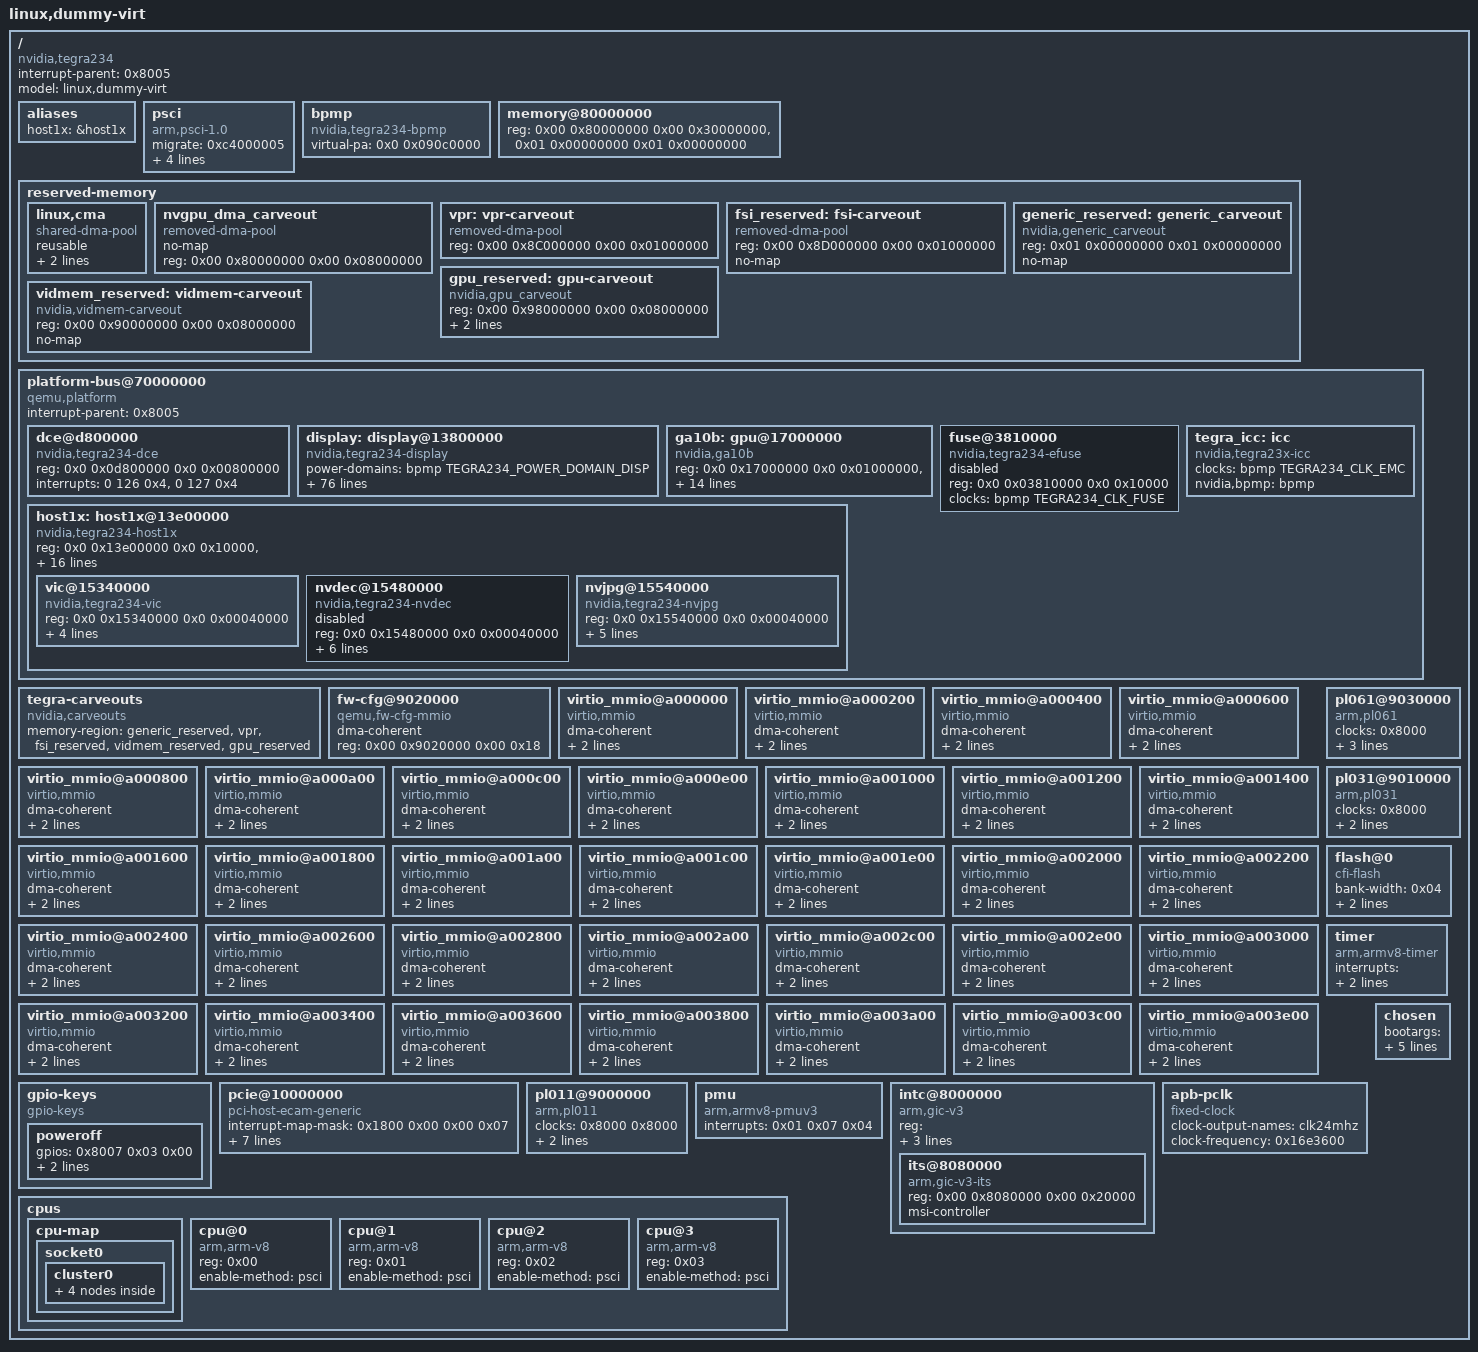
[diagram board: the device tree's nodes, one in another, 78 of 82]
// SPDX-License-Identifier: GPL-2.0-only
// SPDX-FileCopyrightText: Copyright (c) 2023, NVIDIA CORPORATION & AFFILIATES.  All rights reserved.

#include <dt-bindings/clock/tegra234-clock.h>
#include <dt-bindings/reset/tegra234-reset.h>
#include <dt-bindings/mailbox/tegra186-hsp.h>
#include <dt-bindings/memory/tegra234-mc.h>
#include <dt-bindings/interrupt-controller/irq.h>
#include <dt-bindings/interrupt-controller/arm-gic.h>
#include <dt-bindings/interrupt/tegra234-irq.h>
#include <dt-bindings/gpio/tegra234-gpio.h>
#include <dt-bindings/p2u/tegra234-p2u.h>
#include <dt-bindings/power/tegra234-powergate.h>
#include <dt-bindings/pinctrl/pinctrl-tegra.h>

/dts-v1/;


/ {
	interrupt-parent = <0x8005>;
	model = "linux,dummy-virt";
	#size-cells = <0x02>;
	#address-cells = <0x02>;

	// Some drivers need that the root node has this compatible property
	compatible = "nvidia,tegra234";

	aliases {
		host1x = &host1x;
	};

	psci {
		migrate = <0xc4000005>;
		cpu_on = <0xc4000003>;
		cpu_off = <0x84000002>;
		cpu_suspend = <0xc4000001>;
		method = "hvc";
		compatible = "arm,psci-1.0\0arm,psci-0.2\0arm,psci";
	};

	bpmp: bpmp {
		compatible = "nvidia,tegra234-bpmp", "nvidia,tegra186-bpmp";
		virtual-pa = <0x0 0x090c0000>; 
		#clock-cells = <1>;
		#reset-cells = <1>;
		#power-domain-cells = <1>;
		status = "okay";
	};

	// QEMU add the main main memory here (6GB), but we have to define the
	// passthrough memory regions.
	memory@80000000 {
		reg = <0x00 0x80000000 0x00 0x30000000>,  // For CMA regions
		      <0x01 0x00000000 0x01 0x00000000>;  // For GPU VRAM
		device_type = "memory";
	};

	reserved-memory {
		#address-cells = <2>;
		#size-cells = <2>;
		ranges;

		// Reserve the passthrough CMA ram region as CMA for the VM
		linux,cma {
			compatible = "shared-dma-pool";
			reusable;
			reg = <0x00 0x88000000 0x00 0x04000000>; // 64MB
			linux,cma-default;
			status = "okay";
		};

		// Dedicated CMA region for the GPU
		nvgpu_dma_carveout:  nvgpu_dma_carveout{
			compatible = "removed-dma-pool";
			no-map;
			reg = <0x00 0x80000000 0x00 0x08000000>; // 128MB
			status = "okay";
		};

		// Carveout needed by the NVMAP driver
		vpr: vpr-carveout {
			compatible = "removed-dma-pool";
			reg = <0x00 0x8C000000 0x00 0x01000000>; // 16MB
			status = "okay";
		};

		// Carveout needed by the NVMAP driver
		fsi_reserved: fsi-carveout {
			compatible = "removed-dma-pool";
			reg = <0x00 0x8D000000 0x00 0x01000000>; // 16MB
			no-map;
			status = "okay";
		};

		// Carveout for GPU VRAM
		generic_reserved: generic_carveout {
			compatible = "nvidia,generic_carveout";
			reg = <0x01 0x00000000 0x01 0x00000000>; // 4GB
			no-map;
			status = "okay";
		};

		// Carveout needed by the NVMAP driver
		vidmem_reserved: vidmem-carveout {
			compatible = "nvidia,vidmem-carveout";
			reg = <0x00 0x90000000 0x00 0x08000000>; // 128MB
			no-map;
			status = "okay";
		};

		// Carveout for extra GPU DMA operations
		gpu_reserved: gpu-carveout {
			compatible = "nvidia,gpu_carveout";
			reg = <0x00 0x98000000 0x00 0x08000000>; // 128MB
			granule-size = <64>;
			no-map;
			status = "okay";
		};
	};


	platform-bus@70000000 {
		interrupt-parent = <0x8005>;

		// QEMU does not map 1:1 the platform devices, so we have to define the
		// address translation here.
		// To get the address of the devices run in the QEMU console: info mtree -f
		//        From            To              Size
		ranges = <0x00 0x17000000 0x00 0x64000000 0x00 0x01000000>,     // 0x64000000-0000000064ffffff (prio 0, ramd): VFIO 17000000.gpu region 0
		         <0x00 0x18000000 0x00 0x65000000 0x00 0x01000000>,     // 0x65000000-0000000065ffffff (prio 0, ramd): VFIO 17000000.gpu region 1
				 <0x00 0x03b41000 0x00 0x66000000 0x00 0x00001000>,     // 0x66000000-0000000066000fff (prio 0, ramd): VFIO 17000000.gpu region 2
				 <0x00 0x03810000 0x00 0x80000000 0x00 0x00010000>,     // Dummmy address for fues
				 
				 <0x00 0x13800000 0x00 0x66200000 0x00 0x000EFFFF>,     // 0x66200000-00000000662efffe (prio 0, i/o): VFIO 13800000.display region 00
				 <0x00 0x155C0000 0x00 0x660e0000 0x00 0x0000FFFF>,     // 0x660e0000-00000000660efffe (prio 0, i/o): VFIO 13800000.display region 1
				 <0x00 0x0242c000 0x00 0x66001000 0x00 0x00001000>,     // 0x66001000-0000000066001fff (prio 0, ramd): VFIO 13800000.display region 2
				 <0x00 0x03990000 0x00 0x660f0000 0x00 0x00010000>,     // 0x660f0000-00000000660fffff (prio 0, ramd): VFIO 13800000.display region 3
				 
				 <0x00 0x0d800000 0x00 0x66800000 0x00 0x00800000>,     // 0x66800000-0000000066ffffff (prio 0, ramd): VFIO d800000.dce region 0

				 <0x00 0x13e00000 0x00 0x66010000 0x00 0x00010000>,     // 0x66010000-000000006601ffff (prio 0, ramd): VFIO 13e00000.host1x_pt region 0
				 <0x00 0x13e10000 0x00 0x66020000 0x00 0x00010000>,     // 0x66020000-000000006602ffff (prio 0, ramd): VFIO 13e00000.host1x_pt region 1
				 <0x00 0x13e40000 0x00 0x66030000 0x00 0x00010000>,     // 0x66030000-000000006603ffff (prio 0, ramd): VFIO 13e00000.host1x_pt region 2
				 <0x00 0x13ef0000 0x00 0x66080000 0x00 0x00060000>,     // 0x66080000-00000000660dffff (prio 0, ramd): VFIO 13e00000.host1x_pt region 3
				 <0x00 0x15340000 0x00 0x66040000 0x00 0x00040000>,     // 0x66040000-000000006607ffff (prio 0, ramd): VFIO 15340000.vic region 0
				 <0x00 0x15480000 0x00 0x66100000 0x00 0x00040000>,     // 0x66100000-000000006613ffff (prio 0, ramd): VFIO 15480000.nvdec region 0
				 <0x00 0x15540000 0x00 0x66140000 0x00 0x00040000>;     // 0x66140000-000000006617ffff (prio 0, ramd): VFIO 15540000.nvjpg region 0


		#address-cells = <0x02>;
		#size-cells = <0x02>;
		compatible = "qemu,platform\0simple-bus";

		// Here are defined the passthrough devices
		// The commented properties are not needed for the passthrough,
		// or are not supported, because the dependency is not passedthrough 
		// to the VM, for instance the iommus.

		dce@d800000 {
			compatible = "nvidia,tegra234-dce";
			reg = <0x0 0x0d800000 0x0 0x00800000>;
			//dma-coherent;
			interrupts =
				<0 126 0x4>,
				<0 127 0x4>;
			interrupt-names = "wdt-remote",
				"dce-sm0";
			//iommus = <&smmu_niso0 TEGRA234_SID_DCE>;
			status = "okay";
		};


		display: display@13800000 {
			compatible = "nvidia,tegra234-display";
			power-domains = <&bpmp TEGRA234_POWER_DOMAIN_DISP>;
			nvidia,num-dpaux-instance = <1>;
			reg-names = "nvdisplay", "dpaux0", "hdacodec", "mipical";
			reg = <0x0 0x13800000 0x0 0xEFFFF    /* nvdisplay */
				0x0 0x155C0000 0x0 0xFFFF     /* dpaux0 */
				0x0 0x0242c000 0x0 0x1000     /* hdacodec */
				0x0 0x03990000 0x0 0x10000>;  /* mipical */
			interrupt-names = "nvdisplay", "dpaux0", "hdacodec";
			interrupts = <0 128 4
				0 129 4
				0 130 4>;
			nvidia,bpmp = <&bpmp>;
			clocks = <&bpmp TEGRA234_CLK_HUB>,
				<&bpmp TEGRA234_CLK_DISP>,
				<&bpmp TEGRA234_CLK_NVDISPLAY_P0>,
				<&bpmp TEGRA234_CLK_NVDISPLAY_P1>,
				<&bpmp TEGRA234_CLK_DPAUX>,
				<&bpmp TEGRA234_CLK_FUSE>,
				<&bpmp TEGRA234_CLK_DSIPLL_VCO>,
				<&bpmp TEGRA234_CLK_DSIPLL_CLKOUTPN>,
				<&bpmp TEGRA234_CLK_DSIPLL_CLKOUTA>,
				<&bpmp TEGRA234_CLK_SPPLL0_VCO>,
				<&bpmp TEGRA234_CLK_SPPLL0_CLKOUTPN>,
				<&bpmp TEGRA234_CLK_SPPLL0_CLKOUTA>,
				<&bpmp TEGRA234_CLK_SPPLL0_CLKOUTB>,
				<&bpmp TEGRA234_CLK_SPPLL0_DIV10>,
				<&bpmp TEGRA234_CLK_SPPLL0_DIV25>,
				<&bpmp TEGRA234_CLK_SPPLL0_DIV27PN>,
				<&bpmp TEGRA234_CLK_SPPLL1_VCO>,
				<&bpmp TEGRA234_CLK_SPPLL1_CLKOUTPN>,
				<&bpmp TEGRA234_CLK_SPPLL1_DIV27PN>,
				<&bpmp TEGRA234_CLK_VPLL0_REF>,
				<&bpmp TEGRA234_CLK_VPLL0>,
				<&bpmp TEGRA234_CLK_VPLL1>,
				<&bpmp TEGRA234_CLK_NVDISPLAY_P0_REF>,
				<&bpmp TEGRA234_CLK_RG0>,
				<&bpmp TEGRA234_CLK_RG1>,
				<&bpmp TEGRA234_CLK_DISPPLL>,
				<&bpmp TEGRA234_CLK_DISPHUBPLL>,
				<&bpmp TEGRA234_CLK_DSI_LP>,
				<&bpmp TEGRA234_CLK_DSI_CORE>,
				<&bpmp TEGRA234_CLK_DSI_PIXEL>,
				<&bpmp TEGRA234_CLK_PRE_SOR0>,
				<&bpmp TEGRA234_CLK_PRE_SOR1>,
				<&bpmp TEGRA234_CLK_DP_LINK_REF>,
				<&bpmp TEGRA234_CLK_SOR_LINKA_INPUT>,
				<&bpmp TEGRA234_CLK_SOR_LINKA_AFIFO>,
				<&bpmp TEGRA234_CLK_SOR_LINKA_AFIFO_M>,
				<&bpmp TEGRA234_CLK_RG0_M>,
				<&bpmp TEGRA234_CLK_RG1_M>,
				<&bpmp TEGRA234_CLK_SOR0_M>,
				<&bpmp TEGRA234_CLK_SOR1_M>,
				<&bpmp TEGRA234_CLK_PLLHUB>,
				<&bpmp TEGRA234_CLK_SOR0>,
				<&bpmp TEGRA234_CLK_SOR1>,
				<&bpmp TEGRA234_CLK_SOR_PAD_INPUT>,
				<&bpmp TEGRA234_CLK_PRE_SF0>,
				<&bpmp TEGRA234_CLK_SF0>,
				<&bpmp TEGRA234_CLK_SF1>,
				<&bpmp TEGRA234_CLK_DSI_PAD_INPUT>,
				<&bpmp TEGRA234_CLK_PRE_SOR0_REF>,
				<&bpmp TEGRA234_CLK_PRE_SOR1_REF>,
				<&bpmp TEGRA234_CLK_SOR0_PLL_REF>,
				<&bpmp TEGRA234_CLK_SOR1_PLL_REF>,
				<&bpmp TEGRA234_CLK_SOR0_REF>,
				<&bpmp TEGRA234_CLK_SOR1_REF>,
				<&bpmp TEGRA234_CLK_OSC>,
				<&bpmp TEGRA234_CLK_DSC>,
				<&bpmp TEGRA234_CLK_MAUD>,
				<&bpmp TEGRA234_CLK_AZA_2XBIT>,
				<&bpmp TEGRA234_CLK_AZA_BIT>,
				<&bpmp TEGRA234_CLK_MIPI_CAL>,
				<&bpmp TEGRA234_CLK_UART_FST_MIPI_CAL>,
				<&bpmp TEGRA234_CLK_SOR0_DIV>;
			clock-names = "nvdisplayhub_clk",
				"nvdisplay_disp_clk",
				"nvdisplay_p0_clk",
				"nvdisplay_p1_clk",
				"dpaux0_clk",
				"fuse_clk",
				"dsipll_vco_clk",
				"dsipll_clkoutpn_clk",
				"dsipll_clkouta_clk",
				"sppll0_vco_clk",
				"sppll0_clkoutpn_clk",
				"sppll0_clkouta_clk",
				"sppll0_clkoutb_clk",
				"sppll0_div10_clk",
				"sppll0_div25_clk",
				"sppll0_div27_clk",
				"sppll1_vco_clk",
				"sppll1_clkoutpn_clk",
				"sppll1_div27_clk",
				"vpll0_ref_clk",
				"vpll0_clk",
				"vpll1_clk",
				"nvdisplay_p0_ref_clk",
				"rg0_clk",
				"rg1_clk",
				"disppll_clk",
				"disphubpll_clk",
				"dsi_lp_clk",
				"dsi_core_clk",
				"dsi_pixel_clk",
				"pre_sor0_clk",
				"pre_sor1_clk",
				"dp_link_ref_clk",
				"sor_linka_input_clk",
				"sor_linka_afifo_clk",
				"sor_linka_afifo_m_clk",
				"rg0_m_clk",
				"rg1_m_clk",
				"sor0_m_clk",
				"sor1_m_clk",
				"pllhub_clk",
				"sor0_clk",
				"sor1_clk",
				"sor_pad_input_clk",
				"pre_sf0_clk",
				"sf0_clk",
				"sf1_clk",
				"dsi_pad_input_clk",
				"pre_sor0_ref_clk",
				"pre_sor1_ref_clk",
				"sor0_ref_pll_clk",
				"sor1_ref_pll_clk",
				"sor0_ref_clk",
				"sor1_ref_clk",
				"osc_clk",
				"dsc_clk",
				"maud_clk",
				"aza_2xbit_clk",
				"aza_bit_clk",
				"mipi_cal_clk",
				"uart_fst_mipi_cal_clk",
				"sor0_div_clk";
			resets = <&bpmp TEGRA234_RESET_NVDISPLAY>,
				<&bpmp TEGRA234_RESET_DPAUX>,
				<&bpmp TEGRA234_RESET_DSI_CORE>,
				<&bpmp TEGRA234_RESET_MIPI_CAL>;
			reset-names = "nvdisplay_reset",
				"dpaux0_reset",
				"dsi_core_reset",
				"mipi_cal_reset";
			hdcp_enabled;
			status = "okay";
			// We are not passingthrough the framebuffer, becuase the
			// display cann work without it.
			//memory-region = <&fb0_reserved>;
			nvidia,disp-sw-soc-chip-id = <0x2350>;
	// 		interconnects = <&mc TEGRA234_MEMORY_CLIENT_NVDISPLAYR &emc>,
	// 			      <&mc TEGRA234_MEMORY_CLIENT_NVDISPLAYR1 &emc>;
	// 		interconnect-names = "dma-mem", "read-1";
			//iommus = <&smmu_iso TEGRA234_SID_ISO_NVDISPLAY>;
			non-coherent;

			nvidia,dcb-image = [
					55 aa 16 00 00 37 34 30 30 e9 4c 19 77 cc 56 49
					44 45 4f 20 0d 00 00 00 70 01 00 00 00 00 49 42
					4d 20 56 47 41 20 43 6f 6d 70 61 74 69 62 6c 65
					01 00 00 00 10 00 82 18 30 33 2f 31 36 2f 32 33
					00 00 00 00 00 00 00 00 21 18 50 00 e1 2b 00 00
					50 4d 49 44 00 00 00 00 00 00 00 a0 00 b0 00 b8
					00 c0 00 0e 47 41 31 30 42 20 56 47 41 20 42 49
					4f 53 0d 0a 00 00 00 00 00 00 00 00 00 00 00 00
					00 00 00 00 00 00 00 00 00 00 00 00 00 00 00 00
					00 00 00 00 00 00 00 00 00 00 00 00 00 00 00 00
					00 00 00 00 00 00 00 00 00 00 00 00 00 00 00 00
					00 00 00 00 00 56 65 72 73 69 6f 6e 20 39 34 2e
					30 42 2e 30 30 2e 30 30 2e 32 31 20 0d 0a 00 43
					6f 70 79 72 69 67 68 74 20 28 43 29 20 31 39 39
					36 2d 32 30 32 33 20 4e 56 49 44 49 41 20 43 6f
					72 70 2e 0d 0a 00 00 00 ff ff 00 00 00 00 ff ff
					47 50 55 20 42 6f 61 72 64 00 00 00 00 00 00 00
					00 00 00 00 00 00 00 00 00 00 00 00 00 00 00 00
					00 00 00 43 68 69 70 20 52 65 76 20 20 20 00 00
					00 00 00 00 00 00 00 ba 91 98 96 91 9a 9a 8d 96
					91 98 df ad 9a 93 9a 9e 8c 9a df d2 df b1 90 8b
					df b9 90 8d df af 8d 90 9b 8a 9c 8b 96 90 91 df
					aa 8c 9a f2 f5 ff 00 00 00 00 00 00 00 00 00 00
					50 43 49 52 de 10 94 22 00 00 18 00 00 00 00 03
					16 00 01 00 00 80 00 00 2e 8b c0 2e 8b c0 8b c0
					4e 50 44 45 01 01 14 00 16 00 00 01 00 00 00 00
					00 00 00 00 00 00 00 00 00 00 00 00 00 00 00 00
					ff b8 42 49 54 00 00 01 0c 06 13 44 32 01 04 00
					3e 02 42 02 25 00 4a 02 43 02 2c 00 6f 02 44 01
					04 00 9b 02 49 01 24 00 9f 02 4d 02 29 00 c3 02
					4e 00 00 00 00 00 50 02 fc 00 ec 02 53 02 18 00
					e8 03 54 01 02 00 00 04 55 01 05 00 0a 04 56 01
					06 00 0f 04 78 01 08 00 15 04 64 01 02 00 1d 04
					70 02 04 00 1f 04 75 01 11 00 23 04 69 02 6e 00
					34 04 45 01 04 00 02 04 73 01 04 00 06 04 00 00
					a2 04 a2 04 e9 21 f0 21 e0 2b 00 00 00 00 00 00
					00 00 00 00 00 00 00 00 00 00 00 00 0b 94 21 00
					00 00 00 00 a8 07 00 00 00 00 00 00 00 00 02 00
					5c 5c 2e 02 00 00 42 02 04 00 10 00 00 00 00 e9
					0e 00 00 00 00 00 00 3f 44 00 00 e7 2d 00 00 00
					00 00 00 00 00 00 00 00 00 00 00 92 30 00 00 eb
					44 00 00 29 45 00 00 50 45 00 00 00 00 00 00 f6
					04 00 00 00 00 fa 04 00 00 66 08 fa 04 16 2b 66
					08 18 2b a2 04 ef 09 04 22 d4 09 c2 21 18 2b 90
					00 9b 22 01 68 08 56 09 fa 43 00 00 04 44 00 00
					f7 0f 00 00 f0 21 00 00 fc 21 00 00 30 4b 00 00
					00 00 00 00 00 00 00 00 00 00 00 00 d5 33 00 00
					bb 36 00 00 00 00 00 00 00 00 00 00 00 00 00 00
					00 00 00 00 00 00 00 00 00 00 00 00 b3 3c 00 00
					00 00 00 00 ed 3c 00 00 12 43 00 00 00 00 00 00
					00 00 00 00 df 33 00 00 32 3d 00 00 a6 43 00 00
					ad 36 00 00 00 00 00 00 00 00 00 00 c8 43 00 00
					00 00 00 00 00 00 00 00 00 00 00 00 00 00 00 00
					00 00 00 00 61 0b 00 00 dd 0a 00 00 77 0b 00 00
					11 3c 00 00 17 3c 00 00 1c 3c 00 00 20 3c 00 00
					2a 3c 00 00 31 3c 00 00 3f 3c 00 00 81 3c 00 00
					00 00 00 00 00 00 00 00 96 3c 00 00 f6 45 00 00
					9c 47 00 00 11 48 00 00 63 4a 00 00 5c 4c 00 00
					98 4c 00 00 c2 4a 00 00 9c 3c 00 00 79 3c 00 00
					00 00 00 00 00 00 00 00 00 00 00 00 c8 4e 00 00
					a0 3c 00 00 a9 3c 00 00 00 00 00 00 00 00 00 00
					00 00 00 00 00 00 00 00 00 00 00 00 00 00 00 00
					00 00 00 00 00 00 00 00 64 00 50 b5 00 19 cf 00
					28 91 0e 14 a5 0e 23 00 01 23 23 01 14 00 00 00
					0c 11 00 00 00 00 83 17 00 00 c8 0e 01 00 00 0d
					0e df 0c 00 00 00 00 01 01 00 00 00 00 af 1d 0d
					4f 00 00 00 00 00 00 00 00 00 00 00 00 00 00 00
					b2 2d 00 00 00 00 0b 94 21 00 00 66 60 f1 01 f0
					03 00 00 30 33 2f 31 36 2f 32 33 00 00 00 00 00
					00 00 00 00 00 00 00 21 01 10 00 00 00 80 01 00
					00 00 00 00 30 30 30 30 30 30 30 30 30 30 30 30
					00 00 00 00 00 00 00 00 03 42 00 00 1c 06 99 a6
					b9 51 42 01 b8 8b e9 f1 13 c6 1b 3f 54 33 00 00
					00 00 00 00 a5 4d 00 00 00 00 00 00 00 00 73 4f
					00 00 01 00 10 00 bf 09 30 00 02 00 94 22 00 00
					00 00 01 00 44 00 6b 09 00 00 a2 04 00 00 56 09
					00 00 fa 04 00 00 00 00 00 00 66 08 00 00 78 08
					00 00 61 0b 00 00 dd 0a 00 00 77 0b 00 00 8d 0b
					00 00 0d 0e 00 00 df 0c 00 00 00 00 00 00 00 00
					00 00 00 00 00 00 2c 22 00 00 30 c0 61 40 00 00
					00 10 00 00 00 00 08 23 61 00 80 00 00 00 80 00
					00 00 88 23 61 00 80 00 00 00 80 00 00 00 08 24
					61 00 80 00 00 00 80 00 00 00 88 24 61 00 80 00
					00 00 80 00 00 00 08 25 61 00 80 00 00 00 80 00
					00 00 88 25 61 00 80 00 00 00 80 00 00 00 08 26
					61 00 80 00 00 00 80 00 00 00 00 2a 13 00 00 00
					04 00 00 00 04 00 00 2a 13 00 00 00 01 00 00 00
					01 00 00 6e 13 00 00 00 04 00 00 00 04 00 00 6e
					13 00 00 00 01 00 00 00 01 00 4c 00 12 00 3f 00
					00 00 00 00 00 00 0c 24 02 00 01 00 00 00 00 00
					00 00 e4 05 02 00 7c 00 00 00 00 00 00 00 e4 05
					02 00 7c 00 00 00 18 00 00 00 e4 05 02 00 7c 00
					00 00 0c 00 00 00 e4 05 02 00 7c 00 00 00 04 00
					00 00 e4 05 02 00 7c 00 00 00 08 00 00 00 e4 05
					02 00 7c 00 00 00 14 00 00 00 20 0e 9a 00 00 00
					02 00 00 00 02 00 00 0e 9a 00 00 00 02 00 00 00
					02 00 00 0e 9a 00 01 00 00 00 01 00 00 00 34 c0
					61 40 00 00 00 80 00 00 00 00 00 0c 82 00 ff ff
					ff ff 00 00 00 00 00 0c 82 00 01 00 00 00 00 00
					00 00 00 0c 82 00 02 00 00 00 00 00 00 00 00 0c
					82 00 04 00 00 00 00 00 00 00 00 0c 82 00 08 00
					00 00 00 00 00 00 00 0c 82 00 10 00 00 00 00 00
					00 00 00 0c 82 00 20 00 00 00 00 00 00 00 90 02
					82 00 01 00 00 00 00 00 00 00 88 02 82 00 ff 00
					00 00 00 00 00 00 c0 04 82 00 07 00 00 00 00 00
					00 00 00 0a 00 00 00 00 f0 1f 00 00 00 00 88 80
					08 00 00 00 0f 00 00 00 01 00 40 c0 08 00 00 00
					0c 00 00 00 0c 00 40 c0 08 00 1f 00 00 00 00 00
					00 00 00 0a 00 00 00 00 f0 1f 00 00 00 00 74 09
					9a 00 0f 00 00 00 00 00 00 00 e8 73 13 00 01 00
					00 00 01 00 00 00 0c 06 9a 00 40 00 00 00 40 00
					00 00 64 00 12 00 40 00 00 00 40 00 00 00 04 14
					00 00 04 00 00 00 00 00 00 00 04 14 00 00 08 00
					00 00 08 00 00 00 14 38 82 00 00 00 01 00 00 00
					01 00 00 0a 00 00 00 00 f0 1f 00 00 00 00 0c 14
					00 00 01 00 00 00 01 00 00 00 0c 14 00 00 02 00
					00 00 01 00 00 00 88 54 62 00 00 00 01 00 00 00
					00 00 88 54 62 00 00 00 02 00 00 00 00 00 88 54
					62 00 00 00 04 00 00 00 00 00 9c 8b 11 00 00 00
					00 80 00 00 00 00 14 0c 82 00 01 00 00 00 00 00
					00 00 14 0c 82 00 02 00 00 00 00 00 00 00 14 0c
					82 00 04 00 00 00 00 00 00 00 14 0c 82 00 08 00
					00 00 00 00 00 00 14 0c 82 00 10 00 00 00 00 00
					00 00 14 0c 82 00 20 00 00 00 00 00 00 00 9c 8b
					11 00 00 00 00 80 00 00 00 00 10 01 82 00 01 00
					00 00 00 00 00 00 d4 06 82 00 ff 03 00 00 00 00
					00 00 14 0c 82 00 3f 00 00 00 01 00 00 00 00 14
					00 00 02 00 00 00 00 00 00 00 44 c1 61 60 01 00
					00 00 01 00 00 00 20 87 08 00 04 00 00 00 00 00
					00 00 40 00 82 00 01 00 00 00 00 00 00 00 54 9b
					41 00 ff 00 00 00 00 00 00 00 68 9b 41 00 03 00
					00 00 00 00 00 00 40 80 11 00 02 00 00 00 00 00
					00 00 04 0c 82 00 01 00 00 00 00 00 00 00 04 14
					00 00 00 04 00 00 00 00 00 00 34 04 82 00 01 00
					00 00 00 00 00 00 68 08 00 01 02 03 04 05 06 07
					00 01 02 03 04 05 06 07 41 06 24 06 00 00 00 07
					00 02 bf 00 01 51 00 04 bf 00 02 5e 00 01 bf 00
					03 52 00 03 bf 00 84 19 00 00 4f 00 85 7b 59 98
					4f 00 06 ff 00 00 4f 00 07 ff 00 00 ef 00 08 ff
					00 00 ef 00 09 ff 00 00 ef 00 0a ff 00 00 ef 00
					0b ff 00 00 ef 00 0c ff 00 00 ef 00 0d ff 00 00
					ef 00 0e ff 00 00 ef 00 0f ff 00 00 ef 00 10 42
					50 11 e4 00 11 41 42 0b e2 00 12 40 41 0a e1 00
					13 70 51 12 e5 00 14 ff 00 00 ef 00 15 ff 00 00
					ef 00 16 ff 00 00 ef 00 17 ff 00 00 ef 00 18 ff
					00 00 ef 00 19 ff 00 00 ef 00 1a ff 00 00 ef 00
					1b ff 00 00 ef 00 1c ff 00 00 ef 00 1d ff 00 00
					ef 00 1e ff 00 00 ef 00 1f ff 00 00 ef 00 00 ff
					00 00 0f 00 00 ff 00 00 0f 00 00 ff 00 00 0f 00
					00 ff 00 00 0f 00 10 07 16 10 00 bd 0a 01 f0 10
					03 00 00 00 00 ff ff ff 00 ff ff 00 10 00 00 00
					00 00 00 1f 01 00 00 00 00 00 00 ff ff ff 00 ff
					ff 00 10 00 00 00 00 00 00 2f 02 00 00 00 00 00
					00 ff ff ff 00 ff ff 00 10 00 00 00 00 00 00 3f
					03 00 00 00 00 00 00 ff ff ff 00 ff ff 00 10 00
					00 00 00 00 00 4f 04 00 00 00 00 00 00 ff ff ff
					00 ff ff 00 10 00 00 00 00 00 00 5f 05 00 00 00
					00 00 00 ff ff ff 00 ff ff 00 10 00 00 00 00 00
					00 6f 06 00 00 00 00 00 00 ff ff ff 00 ff ff 00
					10 00 00 00 00 00 00 7f 07 00 00 00 00 00 00 ff
					ff ff 00 ff ff 00 10 00 00 00 00 00 00 8f 00 00
					00 00 00 00 00 ff ff ff 00 ff ff 00 10 00 00 00
					00 00 00 9f 01 00 00 00 00 00 00 ff ff ff 00 ff
					ff 00 10 00 00 00 00 00 00 af 02 00 00 00 00 00
					00 ff ff ff 00 ff ff 00 10 00 00 00 00 00 00 bf
					03 00 00 00 00 00 00 ff ff ff 00 ff ff 00 10 00
					00 00 00 00 00 cf 04 00 00 00 00 00 00 ff ff ff
					00 ff ff 00 10 00 00 00 00 00 00 df 05 00 00 00
					00 00 00 ff ff ff 00 ff ff 00 10 00 00 00 00 00
					00 ef 06 00 00 00 00 00 00 ff ff ff 00 ff ff 00
					10 00 00 00 00 00 00 ff 07 00 00 00 00 00 00 ff
					ff ff 00 ff ff 00 10 00 00 00 00 00 00 00 01 02
					03 04 05 06 07 08 09 0a 0b 0c 0d 0e 0f 10 11 12
					13 14 15 16 17 18 19 1a 1b 1c 1d 1e 1f 10 04 20
					04 00 00 80 00 b8 4c 0a ff e0 93 04 00 20 d6 13
					00 e0 93 04 01 20 d6 13 00 ff 00 00 00 00 00 00
					00 00 00 00 00 00 00 00 ff 00 00 00 00 00 00 00
					00 00 00 00 01 00 00 00 00 ff 00 00 00 00 00 00
					00 00 00 00 00 00 00 00 ff 00 00 00 00 00 00 00
					00 00 00 00 01 00 00 00 00 ff 00 00 00 00 00 00
					00 00 00 00 00 00 00 00 ff 00 00 00 00 00 00 00
					00 00 00 00 01 00 00 00 00 ff 00 00 00 00 00 00
					00 20 05 11 01 00 00 35 0c 00 ff ff ff ff ff ff
					ff ff ff 00 00 00 00 10 05 11 01 00 00 00 00 ff
					ff 00 00 00 00 00 00 00 00 00 00 00 00 30 08 10
					01 14 01 15 0e 00 00 00 00 00 00 00 00 00 00 00
					00 00 00 00 00 00 00 00 00 00 00 00 00 00 00 00
					00 00 00 00 00 00 00 00 00 00 00 00 00 00 00 00
					00 00 00 00 00 00 00 00 00 00 00 00 00 00 00 00
					00 00 00 00 00 00 00 00 00 00 00 00 00 00 00 00
					00 00 00 00 00 00 00 00 00 00 00 00 00 00 00 00
					00 00 00 00 00 00 00 00 00 00 00 00 00 00 00 00
					00 00 00 00 00 00 00 00 00 00 00 00 00 00 00 00
					00 00 00 00 00 00 00 00 00 00 00 00 00 00 00 00
					00 00 00 00 00 00 00 00 00 00 00 00 00 00 00 00
					00 00 00 00 00 00 00 00 00 00 00 00 00 00 00 00
					00 00 00 00 00 00 00 00 00 00 00 00 00 00 00 00
					00 00 00 00 00 00 00 00 00 00 00 00 00 00 00 00
					00 00 00 00 00 00 00 00 00 00 00 00 00 00 00 00
					00 00 00 00 00 00 00 00 00 00 00 00 00 00 00 00
					00 00 00 00 00 00 00 00 00 00 00 00 00 00 00 00
					00 00 00 00 00 00 00 00 00 00 00 00 00 00 00 00
					00 00 00 00 00 00 00 00 00 00 00 00 00 00 00 00
					00 00 00 00 00 00 00 00 00 00 00 00 00 00 00 00
					00 00 00 00 00 00 00 00 00 00 00 00 00 00 00 00
					00 00 00 00 00 00 00 00 00 00 00 00 00 00 00 10
					0d 17 34 b0 8f 11 00 00 00 00 00 00 00 00 00 34
					a8 04 82 00 00 00 00 00 00 00 00 00 34 a0 04 82
					00 00 00 00 00 00 00 00 00 34 d4 02 82 00 00 00
					00 00 00 00 00 00 34 a4 04 82 00 00 00 00 00 00
					00 00 00 34 7c 14 00 00 00 00 00 00 00 00 00 00
					34 08 0e 82 00 00 00 00 00 00 00 00 00 34 0c 0e
					82 00 00 00 00 00 00 00 00 00 34 a8 83 11 00 00
					00 00 00 00 00 00 00 34 78 01 82 00 00 00 00 00
					00 00 00 00 34 78 01 82 00 00 00 00 00 00 00 00
					00 34 ac 04 82 00 00 00 00 00 00 00 00 00 34 94
					10 82 00 00 00 00 00 00 00 00 00 34 88 10 82 00
					00 00 00 00 00 00 00 00 34 8c 10 82 00 00 00 00
					00 00 00 00 00 34 90 10 82 00 00 00 00 00 00 00
					00 00 34 ac 83 11 00 00 00 00 00 00 00 00 00 34
					78 01 82 00 00 00 00 00 00 00 00 00 34 d4 02 82
					00 00 00 00 00 00 00 00 00 34 78 05 82 00 00 00
					00 00 00 00 00 00 34 b0 04 82 00 00 00 00 00 00
					00 00 00 34 78 01 82 00 00 00 00 00 00 00 00 00
					34 7c 07 82 00 00 00 00 00 00 00 00 00 10 03 1b
					05 80 00 07 60 05 08 40 08 09 60 0d 0a 40 10 0d
					f0 17 0c e0 15 0e 60 18 0f 40 1c 10 e0 23 15 80
					24 16 26 29 17 60 2d 18 40 30 19 60 35 1a 60 39
					1b 60 3d 1d e0 43 1e a5 44 1f 60 49 20 60 4d 21
					60 51 22 fc 47 23 a0 58 24 66 59 25 2c 5a 26 f2
					5a 68 74 e1 61 8d e9 54 da de d0 33 c4 0d 30 30
					cb 00 00 00 00 00 00 00 00 00 00 00 00 00 00 00
					00 00 00 00 00 00 00 00 00 00 00 00 00 00 00 00
					00 4e 56 49 44 49 41 00 00 00 00 00 00 00 00 00
					00 00 00 00 00 4e 56 49 44 49 41 20 43 6f 72 70
					6f 72 61 74 69 6f 6e 00 00 00 00 00 00 00 00 00
					00 00 00 00 00 00 00 00 22 05 02 0e 0c 00 00 00
					00 00 00 00 00 00 00 00 00 00 00 00 00 00 00 00
					00 00 00 00 00 00 00 00 00 50 04 13 0e 07 95 01
					95 01 d0 07 a0 0f 1b 00 1b 00 0f 0f 32 ff 01 3f
					08 95 01 95 01 d0 07 a0 0f 1b 00 1b 00 0f 0f 32
					ff 01 3f 0b 95 01 95 01 d0 07 a0 0f 1b 00 1b 00
					0f 0f 32 ff 01 3f 04 e1 00 13 01 94 11 28 23 e1
					00 13 01 01 01 14 ff 01 02 0c 1b 00 1b 00 40 06
					80 0c 1b 00 1b 00 01 01 28 ff 01 3f 41 1b 00 1b
					00 40 06 8c 0a 1b 00 28 00 01 ff 28 ff 03 3f 42
					1b 00 1b 00 40 06 8c 0a 1b 00 28 00 01 ff 28 ff
					03 3f 80 1b 00 1b 00 20 03 54 06 1b 00 1b 00 01
					01 14 ff 01 3f 81 1b 00 1b 00 20 03 54 06 1b 00
					1b 00 01 01 14 ff 01 3f 82 1b 00 1b 00 20 03 54
					06 1b 00 1b 00 01 01 14 ff 01 3f 83 1b 00 1b 00
					20 03 54 06 1b 00 1b 00 01 01 14 ff 01 3f 0d 1b
					00 1b 00 20 03 54 06 1b 00 1b 00 01 01 14 ff 01
					3f 0e 1b 00 1b 00 e8 03 d0 07 0d 00 1b 00 01 ff
					28 ff 01 1f 0f 95 01 95 01 d0 07 a0 0f 1b 00 1b
					00 0f 0f 32 ff 01 3f 10 04 02 06 00 00 00 07 00
					07 00 07 00 07 00 07 10 05 04 10 04 0f 0f 0f 0f
					2f 2f 2f 2f 1c 1c 1c 1c 0f 46 40 00 0e 0e 0e 0e
					2d 2d 2d 2d 13 13 13 13 0f 46 40 00 0e 0e 0e 0e
					2c 2c 2c 2c 15 15 15 15 0f 46 40 00 0e 0e 0e 0e
					2b 2b 2b 2b 17 17 17 17 0f 46 40 00 0f 0f 0f 0f
					2d 2d 2d 2d 19 19 19 19 0f 46 40 00 0f 0f 0f 0f
					2c 2c 2c 2c 1b 1b 1b 1b 0f 46 40 00 0f 0f 0f 0f
					2b 2b 2b 2b 1d 1d 1d 1d 0f 46 40 00 0f 0f 0f 0f
					2a 2a 2a 2a 1f 1f 1f 1f 0f 46 40 00 0e 0e 0e 0e
					29 29 29 29 18 18 18 18 0f 46 40 00 0e 0e 0e 0e
					28 28 28 28 1a 1a 1a 1a 0f 46 40 00 0e 0e 0e 0e
					27 27 27 27 1c 1c 1c 1c 0f 46 40 00 0e 0e 0e 0e
					26 26 26 26 1e 1e 1e 1e 0f 46 40 00 0f 0f 0f 0f
					2d 2d 2d 2d 19 19 19 19 0f 46 40 00 0f 0f 0f 0f
					2c 2c 2c 2c 1b 1b 1b 1b 0f 46 40 00 0f 0f 0f 0f
					2b 2b 2b 2b 1d 1d 1d 1d 0f 46 40 00 0f 0f 0f 0f
					2a 2a 2a 2a 1f 1f 1f 1f 0f 46 40 00 20 19 04 00
					00 50 32 74 40 e8 80 e4 57 01 04 04 06 31 1a 00
					00 07 10 00 00 3d 11 00 00 3b 12 00 00 39 13 00
					00 37 14 00 00 35 15 00 00 33 16 00 00 10 08 0e
					05 00 2c 04 04 d1 84 00 00 00 00 0a 05 00 06 00
					00 00 00 00 38 3d 3e 3f 3a 00 00 00 00 05 05 05
					05 00 00 00 00 00 00 00 00 88 58 24 00 00 00 00
					00 75 40 00 00 00 00 0a 05 00 06 00 00 00 00 00
					38 3d 3e 3f 3a 3f 3f 3f 3f 05 05 05 05 0a 0a 0a
					0a 00 00 00 00 88 58 24 00 aa aa 00 00 65 19 00
					00 00 00 0a 05 00 06 00 00 00 00 00 48 3a 3a 3a
					3a 3a 3a 3a 3a 00 00 00 00 00 00 00 00 00 00 00
					00 f8 5a 24 00 aa aa 00 00 00 00 00 00 00 00 0a
					0a 00 06 00 00 00 00 00 58 3a 3a 3a 3a 3a 3a 3a
					3a 00 00 00 00 00 00 00 00 00 00 00 00 f8 5a 24
					00 aa aa 00 00 03 00 00 01 0a 05 0f 46 40 00 00
					03 00 44 06 00 00 01 0a 08 0f 46 40 00 00 03 00
					44 08 00 00 01 0a 05 0f 46 40 00 00 03 00 44 0a
					00 00 01 0a 05 0f 46 40 00 00 03 00 44 0c 00 00
					01 0a 08 0f 46 40 00 00 03 00 44 10 08 0e 05 00
					2c 04 04 d1 84 00 00 00 00 0a 05 00 06 00 00 00
					00 00 38 3d 3e 3f 3a 00 00 00 00 05 05 05 05 00
					00 00 00 00 00 00 00 88 58 24 00 00 00 00 00 75
					40 00 00 00 00 0a 05 00 06 00 00 00 00 00 38 3d
					3e 3f 3a 00 00 00 00 05 05 05 05 00 00 00 00 00
					00 00 00 88 58 24 00 00 00 00 00 65 19 00 00 00
					00 0a 05 00 06 00 00 00 00 00 48 3a 3a 3a 3a 00
					00 00 00 00 00 00 00 00 00 00 00 00 00 00 00 f8
					5a 24 00 00 00 00 00 00 00 00 00 00 00 0a 0a 00
					06 00 00 00 00 00 58 3a 3a 3a 3a 00 00 00 00 00
					00 00 00 00 00 00 00 00 00 00 00 f8 5a 24 00 00
					00 00 00 0c 00 00 01 0a 05 0f 46 40 00 00 03 00
					44 0d 00 00 01 0a 08 0f 46 40 00 00 03 00 44 0e
					00 00 01 0a 05 0f 46 40 00 00 03 00 44 0f 01 00
					01 0a 05 0f 46 40 00 00 03 00 44 10 01 00 01 0a
					08 0f 46 40 00 00 03 00 44 10 08 0e 05 00 2c 04
					04 d1 84 00 00 00 00 0a 05 00 06 00 00 00 00 00
					38 3d 3e 3f 3a 00 00 00 00 05 05 05 05 00 00 00
					00 00 00 00 00 88 58 24 00 00 00 00 00 75 40 00
					00 00 00 0a 05 00 06 00 00 00 00 00 38 3d 3e 3f
					3a 3f 3f 3f 3f 05 05 05 05 05 05 05 05 00 00 00
					00 88 58 24 00 00 00 00 00 65 19 00 00 00 00 0a
					05 00 06 00 00 00 00 00 48 3a 3a 3a 3a 3a 3a 3a
					3a 00 00 00 00 00 00 00 00 00 00 00 00 f8 5a 24
					00 00 00 00 00 00 00 00 00 00 00 0a 0a 00 06 00
					00 00 00 00 58 3a 3a 3a 3a 3a 3a 3a 3a 00 00 00
					00 00 00 00 00 00 00 00 00 f8 5a 24 00 00 00 00
					00 0c 01 00 01 0a 05 0f 46 40 00 00 03 00 44 0d
					01 00 01 0a 08 0f 46 40 00 00 03 00 44 0e 02 00
					01 0a 05 0f 46 40 00 00 03 00 44 0f 02 00 01 0a
					05 0f 46 40 00 00 03 00 44 10 02 00 01 0a 08 0f
					46 40 00 00 03 00 44 10 08 0e 05 00 2c 04 04 d1
					84 00 00 00 00 0a 05 00 06 00 00 00 00 00 38 3d
					3e 3f 3a 00 00 00 00 05 05 05 05 00 00 00 00 00
					00 00 00 88 58 24 00 00 00 00 00 75 40 00 00 00
					00 0a 05 00 06 00 00 00 00 00 38 3d 3e 3f 3a 00
					00 00 00 05 05 05 05 00 00 00 00 00 00 00 00 88
					58 24 00 00 00 00 00 65 19 00 00 00 00 0a 05 00
					06 00 00 00 00 00 48 3a 3a 3a 3a 00 00 00 00 00
					00 00 00 00 00 00 00 00 00 00 00 f8 5a 24 00 00
					00 00 00 00 00 00 00 00 00 0a 0a 00 06 00 00 00
					00 00 58 3a 3a 3a 3a 00 00 00 00 00 00 00 00 00
					00 00 00 00 00 00 00 f8 5a 24 00 00 00 00 00 0c
					00 00 01 0a 05 0f 46 40 00 00 03 00 44 0d 00 00
					01 0a 08 0f 46 40 00 00 03 00 44 0e 00 00 01 0a
					05 0f 46 40 00 00 03 00 44 0f 01 00 01 0a 05 0f
					46 40 00 00 03 00 44 10 01 00 01 0a 08 0f 46 40
					00 00 03 00 44 10 08 0e 05 00 2c 04 04 d1 84 00
					00 00 00 0a 05 00 06 00 00 00 00 00 38 3d 3e 3f
					3a 00 00 00 00 05 05 05 05 00 00 00 00 00 00 00
					00 88 58 24 00 00 00 00 00 75 40 00 00 00 00 0a
					05 00 06 00 00 00 00 00 38 3d 3e 3f 3a 3f 3f 3f
					3f 05 05 05 05 08 08 08 08 00 00 00 00 88 58 24
					00 00 00 00 00 65 19 00 00 00 00 0a 05 00 06 00
					00 00 00 00 48 3a 3a 3a 3a 3a 3a 3a 3a 00 00 00
					00 00 00 00 00 00 00 00 00 f8 5a 24 00 00 00 00
					00 00 00 00 00 00 00 0a 0a 00 06 00 00 00 00 00
					58 3a 3a 3a 3a 3a 3a 3a 3a 00 00 00 00 00 00 00
					00 00 00 00 00 f8 5a 24 00 00 00 00 00 0c 01 00
					01 0a 05 0f 46 40 00 00 03 00 44 0d 01 00 01 0a
					08 0f 46 40 00 00 03 00 44 0e 02 00 01 0a 05 0f
					46 40 00 00 03 00 44 0f 02 00 01 0a 05 0f 46 40
					00 00 03 00 44 10 02 00 01 0a 08 0f 46 40 00 00
					03 00 44 10 08 0e 05 00 2c 04 04 d1 84 00 00 00
					00 0a 05 00 06 00 00 00 00 00 38 3d 3e 3f 3a 00
					00 00 00 05 05 05 05 00 00 00 00 00 00 00 00 88
					58 24 00 00 00 00 00 75 40 00 00 00 00 0a 05 00
					06 00 00 00 00 00 38 3d 3e 3f 3a 00 00 00 00 05
					05 05 05 00 00 00 00 00 00 00 00 88 58 24 00 00
					00 00 00 65 19 00 00 00 00 0a 05 00 06 00 00 00
					00 00 48 3a 3a 3a 3a 00 00 00 00 00 00 00 00 00
					00 00 00 00 00 00 00 f8 5a 24 00 00 00 00 00 00
					00 00 00 00 00 0a 0a 00 06 00 00 00 00 00 58 3a
					3a 3a 3a 00 00 00 00 00 00 00 00 00 00 00 00 00
					00 00 00 f8 5a 24 00 00 00 00 00 0c 00 00 01 0a
					05 0f 46 40 00 00 03 00 44 0d 00 00 01 0a 08 0f
					46 40 00 00 03 00 44 0e 00 00 01 0a 05 0f 46 40
					00 00 03 00 44 0f 01 00 01 0a 05 0f 46 40 00 00
					03 00 44 10 01 00 01 0a 08 0f 46 40 00 00 03 00
					44 7a 14 c0 61 40 01 00 c2 0d 74 05 00 6e 14 c0
					61 40 ff ff bf ff 00 00 00 00 6e e4 c5 61 40 fe
					ff ff ff 00 00 00 00 71 5b b0 1a 71 5b 63 17 5b
					68 17 71 56 00 ff 72 71 6e 0c c1 61 40 fe ff ff
					ff 00 00 00 00 6e 40 65 61 80 fe ff ff ff 00 00
					00 00 71 10 07 01 60 01 60 00 00 00 00 00 00 00
					00 00 00 00 00 00 00 00 00 00 00 00 00 00 00 00
					00 00 00 00 00 00 00 00 00 00 00 00 00 00 00 00
					00 00 00 00 00 00 00 00 00 00 00 00 00 00 00 00
					00 00 00 00 00 00 00 00 00 00 00 00 00 00 00 00
					00 00 00 00 00 00 00 00 00 00 00 00 00 00 00 00
					00 00 00 00 00 00 00 00 00 00 00 00 00 00 00 00
					00 00 00 00 00 00 00 00 00 00 00 00 00 00 00 00
					00 00 00 00 00 00 00 00 00 00 00 00 00 00 00 00
					00 00 00 00 00 00 00 00 00 00 00 00 00 00 00 00
					00 00 00 00 00 00 00 00 00 00 00 00 00 00 00 00
					00 00 00 00 00 00 00 00 00 00 00 00 00 00 00 00
					00 00 00 00 00 00 00 00 00 00 6e 00 23 61 40 ff
					ff 80 fc 00 00 23 00 71 6e 00 23 61 40 ff ff 80
					fc 00 00 27 00 71 6e 00 23 61 40 ff ff 80 fc 00
					00 2b 00 71 6e 00 23 61 40 ff ff 80 fc 00 00 2f
					00 71 41 23 10 08 25 19 cb bd dc 4e 78 08 00 00
					00 00 00 00 67 19 ec 19 c1 00 00 00 00 00 00 00
					00 00 00 00 00 02 03 80 01 10 00 62 04 0e 01 80
					01 10 00 02 04 0e 11 02 01 10 00 02 00 2e 32 03
					02 10 00 02 00 fe 40 04 00 00 00 00 00 0f 00 00
					00 00 00 00 00 0f 00 00 00 00 00 00 00 0f 00 00
					00 00 00 00 00 0f 00 00 00 00 00 00 00 0f 00 00
					00 00 00 00 00 0f 00 00 00 00 00 00 00 0f 00 00
					00 00 00 00 00 0f 00 00 00 00 00 00 00 0f 00 00
					00 00 00 00 00 0f 00 00 00 00 00 00 00 0f 00 00
					00 00 00 00 00 41 06 0f 04 02 0f 06 00 00 10 ff
					03 00 80 ff 03 00 80 ff 03 00 10 ff 03 00 10 ff
					03 00 10 ff 03 00 10 ff 03 00 10 ff 03 00 10 ff
					03 00 10 ff 03 00 00 ff 03 00 00 ff 03 00 00 ff
					03 00 00 ff 03 00 00 40 05 20 04 01 ff 00 00 00
					ff 00 00 00 ff 00 00 00 ff 00 00 00 ff 00 00 00
					ff 00 00 00 ff 00 00 00 ff 00 00 00 ff 00 00 00
					ff 00 00 00 ff 00 00 00 ff 00 00 00 ff 00 00 00
					ff 00 00 00 ff 00 00 00 ff 00 00 00 ff 00 00 00
					ff 00 00 00 ff 00 00 00 ff 00 00 00 ff 00 00 00
					ff 00 00 00 ff 00 00 00 ff 00 00 00 ff 00 00 00
					ff 00 00 00 ff 00 00 00 ff 00 00 00 ff 00 00 00
					ff 00 00 00 ff 00 00 00 ff 00 00 00 40 05 10 04
					00 61 10 00 00 ff 01 00 00 ff 02 00 00 ff 03 00
					00 ff 04 00 00 ff 00 00 00 ff 00 00 00 ff 00 00
					00 ff 00 00 00 ff 00 00 00 ff 00 00 00 ff 00 00
					00 ff 00 00 00 ff 00 00 00 ff 00 00 00 ff 00 00
					00 10 05 40 01 00 00 00 0b 03 00 00 0a 02 00 00
					08 02 00 20 04 02 00 80 00 00 00 80 00 00 00 80
					00 00 00 80 00 00 00 20 00 00 00 20 00 03 00 00
					0c 03 00 00 0a 03 00 80 0b 03 00 80 0b 03 00 80
					0b 03 00 80 0b 03 71 71 6e 14 c0 61 40 ff ff 3f
					fa 00 00 c0 01 74 05 00 6e 14 c0 61 40 f7 ff ff
					ff 08 00 00 00 6e b8 c1 61 40 ff ff 3f 81 00 03
					00 08 6e 00 23 61 40 ff ff 83 fc 00 00 00 00 71
					58 40 c0 61 40 10 00 00 0a 1d 00 00 0a 04 00 00
					08 04 00 20 04 04 00 80 00 00 00 80 00 00 00 80
					00 00 00 80 00 00 00 20 00 00 00 20 00 1d 00 00
					0c 1d 00 00 0a 1d 00 80 0a 1d 00 80 0a 1d 00 80
					0a 1d 00 80 0a 1d 71 6e 00 23 61 40 ff ff fc fc
					00 00 02 03 71 7a 14 c0 61 40 14 00 c2 0d 74 05
					00 6e 14 c0 61 40 ff ff bf ff 00 00 00 00 74 14
					00 71 6e 14 c0 61 40 ff ff ff f2 00 00 00 00 74
					0a 00 6e 00 23 61 40 ff ff fc ff 00 00 01 00 6e
					0c c1 61 60 ff bf ff ff 00 40 00 00 6e 14 c0 61
					40 ff ff 7f ff 00 00 00 00 6e 30 c1 61 60 f0 ff
					ff ff 0f 00 00 00 6e 34 c0 61 40 ff ff ee 7f 00
					00 00 80 56 17 ff 6e 0c c1 61 60 fc ff ff ff 01
					00 00 00 6e 30 c1 61 60 0f ff ff ff f0 00 00 00
					74 0a 00 6e 30 c1 61 60 0f ff ff ff 00 00 00 00
					6e 10 c1 61 40 e0 e0 e0 e0 00 00 00 00 6e 2c c1
					61 40 e0 e0 e0 e0 00 00 00 00 3a 05 15 6e 40 c1
					61 60 fd ff ff ff 02 00 00 00 98 0a 01 00 00 01
					fe 01 71 98 02 01 00 00 01 d0 00 6e 10 c1 61 40
					e0 e0 e0 e0 10 10 10 10 6e 2c c1 61 40 e0 e0 e0
					e0 10 10 10 10 71 5f 0c c1 61 60 00 01 40 ff 40
					00 00 00 00 40 65 61 80 fe bf 00 bf 3a 00 03 5b
					14 1c 72 71 3a 07 01 38 6e 40 c1 61 60 fe ff ff
					ff 01 00 00 00 72 5b 68 1d 52 e8 df 00 71 71 6e
					0c c1 61 60 fe ff 00 ff 00 00 00 00 6e 30 c1 61
					40 f0 ff ff ff 00 00 00 00 6e b0 c1 61 40 f0 ff
					ff ff 00 00 00 00 6e 34 c0 61 40 ff ff ee 7f 00
					00 11 80 56 17 ff 6e 14 c0 61 40 ff ff 7f ff 00
					00 80 00 6e 00 23 61 40 ff ff fc ff 00 00 02 00
					74 05 00 6e 14 c0 61 40 ff ff ff f2 00 00 00 0d
					74 05 00 6e 14 c0 61 40 ff ff bf ff 00 00 40 00
					74 05 00 6e 14 c0 61 40 f7 ff ff ff 08 00 00 00
					6e 0c c0 61 40 ff f0 f0 f0 00 03 05 05 6e b8 c1
					61 40 ff ff ff 81 00 03 00 08 6e 00 23 61 40 ff
					ff 83 fc 00 00 00 00 6e 40 c1 61 60 fe ff ff ff
					00 00 00 00 71 6e 0c c1 61 60 fd ff ff ff 02 00
					00 00 6e 30 c1 61 60 ff ff bf ff 00 00 40 00 71
					10 05 40 01 01 00 00 00 00 0a 10 00 00 00 a0 40
					00 00 80 40 00 00 80 40 00 00 80 40 00 00 80 40
					00 00 80 40 00 00 20 00 00 32 10 80 00 0a 90 80
					00 00 80 80 00 00 80 80 00 00 80 80 00 00 80 80
					00 00 80 80 00 71 71 6e 40 65 61 80 fe ff ff ff
					00 00 00 00 71 71 98 07 01 00 00 01 ef 10 71 98
					07 01 00 00 01 ef 00 71 58 40 c0 61 40 10 00 00
					00 00 32 10 00 00 00 a0 40 00 00 80 40 00 00 80
					40 00 00 80 40 00 00 80 40 00 00 80 40 00 00 20
					00 00 32 10 80 00 96 90 80 00 00 80 80 00 00 80
					80 00 00 80 80 00 00 80 80 00 00 80 80 00 71 42
					15 02 07 13 04 03 0a 04 28 23 28 23 01 04 04 06
					00 1d 00 00 00 00 00 00 00 00 00 00 00 00 00 00
					00 00 14 00 02 19 0a 03 1e 14 04 2b 28 06 1e 00
					03 25 0f 04 2f 21 06 28 00 04 32 14 06 3c 00 06
					14 00 02 19 0a 03 1e 14 04 2b 28 06 1e 00 03 25
					0f 04 2f 21 06 28 00 04 32 14 06 3c 00 06 14 00
					02 19 0a 03 1e 14 04 2b 28 06 1e 00 03 25 0f 04
					2f 21 06 28 00 04 32 14 06 3c 00 06 0f 00 02 16
					09 03 1d 0e 04 27 12 06 17 00 03 21 09 04 27 0e
					06 1f 00 04 27 09 06 27 00 06 62 1e 00 00 f2 1e
					00 00 82 1f 00 00 12 20 00 00 a2 20 00 00 32 21
					00 00 10 08 00 00 00 11 08 00 1e 00 00 00 00 01
					05 05 00 40 00 00 00 00 00 30 00 14 00 00 00 00
					01 05 05 00 40 00 00 00 00 00 30 00 10 00 00 00
					00 01 05 05 00 40 00 00 00 00 00 30 00 0c 00 00
					00 00 01 05 05 00 40 00 00 00 00 00 30 00 0a 00
					00 00 00 01 05 05 00 40 00 00 00 00 00 30 00 09
					00 00 00 00 01 05 05 00 40 00 00 00 00 00 30 00
					08 00 00 00 00 01 05 05 00 40 00 00 00 00 00 30
					00 06 00 00 00 00 01 05 05 00 40 00 00 00 00 00
					30 00 10 08 00 00 00 11 08 00 1e 00 00 00 00 00
					05 05 00 00 00 00 00 00 00 00 00 14 00 00 00 00
					00 05 05 00 00 00 00 00 00 00 00 00 10 00 00 00
					00 03 00 01 00 50 00 00 00 00 00 00 00 0c 00 00
					00 00 03 00 01 00 50 00 00 00 00 00 00 00 0a 00
					00 00 00 00 05 05 00 00 00 00 00 00 00 00 00 09
					00 00 00 00 03 00 01 00 40 00 00 00 00 00 00 00
					08 00 00 00 00 03 00 01 00 40 00 00 00 00 00 00
					00 06 00 00 00 00 00 05 05 00 00 00 00 00 00 00
					00 00 10 08 00 00 00 11 08 00 1e 00 00 00 00 00
					05 05 00 00 00 00 00 00 00 00 00 14 00 00 00 00
					00 05 05 00 00 00 00 00 00 00 00 00 10 00 00 00
					00 03 00 01 00 50 00 00 00 00 00 00 00 0c 00 00
					00 00 03 00 01 00 50 00 00 00 00 00 00 00 0a 00
					00 00 00 00 05 05 00 00 00 00 00 00 00 00 00 09
					00 00 00 00 03 00 01 00 40 00 00 00 00 00 00 00
					08 00 00 00 00 03 00 01 00 40 00 00 00 00 00 00
					00 06 00 00 00 00 00 05 05 00 00 00 00 00 00 00
					00 00 10 08 00 00 00 11 08 00 1e 00 00 00 00 00
					05 05 00 00 00 00 00 00 00 00 00 14 00 00 00 00
					00 05 05 00 00 00 00 00 00 00 00 00 10 00 00 00
					00 03 00 01 00 50 00 00 00 00 00 00 00 0c 00 00
					00 00 03 00 01 00 50 00 00 00 00 00 00 00 0a 00
					00 00 00 00 05 05 00 00 00 00 00 00 00 00 00 09
					00 00 00 00 03 00 01 00 40 00 00 00 00 00 00 00
					08 00 00 00 00 03 00 01 00 40 00 00 00 00 00 00
					00 06 00 00 00 00 00 05 05 00 00 00 00 00 00 00
					00 00 10 08 00 00 00 11 08 00 1e 00 00 00 00 00
					05 05 00 00 00 00 00 00 00 00 00 14 00 00 00 00
					00 05 05 00 00 00 00 00 00 00 00 00 10 00 00 00
					00 03 00 01 00 50 00 00 00 00 00 00 00 0c 00 00
					00 00 03 00 01 00 50 00 00 00 00 00 00 00 0a 00
					00 00 00 00 05 05 00 00 00 00 00 00 00 00 00 09
					00 00 00 00 03 00 01 00 40 00 00 00 00 00 00 00
					08 00 00 00 00 03 00 01 00 40 00 00 00 00 00 00
					00 06 00 00 00 00 00 05 05 00 00 00 00 00 00 00
					00 00 10 08 00 00 00 11 08 00 1e 00 00 00 00 00
					05 05 00 00 00 00 00 00 00 00 00 14 00 00 00 00
					00 05 05 00 00 00 00 00 00 00 00 00 10 00 00 00
					00 03 00 01 00 50 00 00 00 00 00 00 00 0c 00 00
					00 00 03 00 01 00 50 00 00 00 00 00 00 00 0a 00
					00 00 00 00 05 05 00 00 00 00 00 00 00 00 00 09
					00 00 00 00 03 00 01 00 40 00 00 00 00 00 00 00
					08 00 00 00 00 03 00 01 00 40 00 00 00 00 00 00
					00 06 00 00 00 00 00 05 05 00 00 00 00 00 00 00
					00 00 ];

		};


		ga10b: gpu@17000000 {
			compatible = "nvidia,ga10b";
			reg = <0x0 0x17000000 0x0 0x01000000>,
			      <0x0 0x18000000 0x0 0x01000000>,
			      <0x0 0x03b41000 0x0 0x00001000>;
			interrupt-parent = <0x8005>;
			interrupts = <GIC_SPI 112 IRQ_TYPE_LEVEL_HIGH>,
				     <GIC_SPI 113 IRQ_TYPE_LEVEL_HIGH>,
				     <GIC_SPI 114 IRQ_TYPE_LEVEL_HIGH>,
				     <GIC_SPI 115 IRQ_TYPE_LEVEL_HIGH>;
			interrupt-names = "stall0", "stall1", "stall2", "nonstall";
			power-domains = <&bpmp TEGRA234_POWER_DOMAIN_GPU>;
			//interconnects = <&mc TEGRA234_MEMORY_CLIENT_NVL1R &emc>,
			//		<&mc TEGRA234_MEMORY_CLIENT_NVL1W &emc>;
			//interconnect-names = "dma-mem", "write";
			clocks = <&bpmp TEGRA234_CLK_GPUSYS>,
				 <&bpmp TEGRA234_CLK_GPC0CLK>,
				 <&bpmp TEGRA234_CLK_GPC1CLK>;
			clock-names = "sysclk", "gpc0clk", "gpc1clk";
			resets = <&bpmp TEGRA234_RESET_GPU>;
			dma-coherent;
			nvidia,bpmp = <&bpmp>;

			status = "okay";
		};

		// We need to keep fuse here disable without passing
		// through in order the display works
		fuse@3810000 {
			compatible = "nvidia,tegra234-efuse";
			reg = <0x0 0x03810000 0x0 0x10000>;
			clocks = <&bpmp TEGRA234_CLK_FUSE>;
			clock-names = "fuse";
			status = "disabled";
		};


		tegra_icc: icc {
			#interconnect-cells = <1>;
			clocks = <&bpmp TEGRA234_CLK_EMC>;
			clock-names = "emc";
			compatible = "nvidia,tegra23x-icc";
			nvidia,bpmp = <&bpmp>;
			status = "okay";
		};


		host1x: host1x@13e00000 {
			compatible = "nvidia,tegra234-host1x";
			reg = <0x0 0x13e00000 0x0 0x10000>,
			      <0x0 0x13e10000 0x0 0x10000>,
			      <0x0 0x13e40000 0x0 0x10000>,
			      <0x0 0x13ef0000 0x0 0x60000>;
			reg-names = "common", "hypervisor", "vm", "actmon";

			clocks = <&bpmp TEGRA234_CLK_HOST1X>,
				 <&bpmp TEGRA234_CLK_ACTMON>;
			clock-names = "host1x", "actmon";
			assigned-clocks = <&bpmp TEGRA234_CLK_HOST1X>;
			assigned-clock-rates = <204000000>;

			interrupts = <GIC_SPI 116 IRQ_TYPE_LEVEL_HIGH>,
				     <GIC_SPI 117 IRQ_TYPE_LEVEL_HIGH>,
				     <GIC_SPI 118 IRQ_TYPE_LEVEL_HIGH>,
				     <GIC_SPI 119 IRQ_TYPE_LEVEL_HIGH>,
				     <GIC_SPI 120 IRQ_TYPE_LEVEL_HIGH>,
				     <GIC_SPI 121 IRQ_TYPE_LEVEL_HIGH>,
				     <GIC_SPI 122 IRQ_TYPE_LEVEL_HIGH>,
				     <GIC_SPI 123 IRQ_TYPE_LEVEL_HIGH>,
				     <GIC_SPI 124 IRQ_TYPE_LEVEL_HIGH>;
			interrupt-names = "syncpt0", "syncpt1", "syncpt2", "syncpt3", "syncpt4",
					  "syncpt5", "syncpt6", "syncpt7", "host1x";


			#address-cells = <2>;
			#size-cells = <2>;

			// IOMMUs and interconnects are needed for nvdec, in order to avoid error 
			// tegra-nvdec 15480000.nvdec: multiqueue0:src: job submission failed: host1x job submission failed: -1
			//interconnects = <&mc TEGRA234_MEMORY_CLIENT_HOST1XDMAR &emc>;
			//interconnect-names = "dma-mem";
			//iommus = <&smmu_niso1 TEGRA234_SID_HOST1X>;
			//dma-coherent;

			//interrupt-parent = <&gic>;

			ranges = <0x0 0x14800000 0x0 0x14800000 0x0 0x02000000>,
				 <0x0 0x24700000 0x0 0x24700000 0x0 0x00080000>;

			status = "okay";

			/* Context isolation domains */
			// iommu-map = <0 &smmu_niso0 TEGRA234_SID_HOST1X_CTX0 1>,
			// 	    <1 &smmu_niso0 TEGRA234_SID_HOST1X_CTX1 1>,
			// 	    <2 &smmu_niso0 TEGRA234_SID_HOST1X_CTX2 1>,
			// 	    <3 &smmu_niso0 TEGRA234_SID_HOST1X_CTX3 1>,
			// 	    <4 &smmu_niso0 TEGRA234_SID_HOST1X_CTX4 1>,
			// 	    <5 &smmu_niso0 TEGRA234_SID_HOST1X_CTX5 1>,
			// 	    <6 &smmu_niso0 TEGRA234_SID_HOST1X_CTX6 1>,
			// 	    <7 &smmu_niso0 TEGRA234_SID_HOST1X_CTX7 1>,
			// 	    <8 &smmu_niso1 TEGRA234_SID_HOST1X_CTX0 1>,
			// 	    <9 &smmu_niso1 TEGRA234_SID_HOST1X_CTX1 1>,
			// 	    <10 &smmu_niso1 TEGRA234_SID_HOST1X_CTX2 1>,
			// 	    <11 &smmu_niso1 TEGRA234_SID_HOST1X_CTX3 1>,
			// 	    <12 &smmu_niso1 TEGRA234_SID_HOST1X_CTX4 1>,
			// 	    <13 &smmu_niso1 TEGRA234_SID_HOST1X_CTX5 1>,
			// 	    <14 &smmu_niso1 TEGRA234_SID_HOST1X_CTX6 1>,
			// 	    <15 &smmu_niso1 TEGRA234_SID_HOST1X_CTX7 1>;

			vic@15340000 {
				compatible = "nvidia,tegra234-vic";
				reg = <0x0 0x15340000 0x0 0x00040000>;
				interrupts = <GIC_SPI 125 IRQ_TYPE_LEVEL_HIGH>;
				clocks = <&bpmp TEGRA234_CLK_VIC>;
				clock-names = "vic";
				resets = <&bpmp TEGRA234_RESET_VIC>;
				reset-names = "vic";

				power-domains = <&bpmp TEGRA234_POWER_DOMAIN_VIC>;
				// interconnects = <&mc TEGRA234_MEMORY_CLIENT_VICSRD &emc>,
				// 		<&mc TEGRA234_MEMORY_CLIENT_VICSWR &emc>;
				// interconnect-names = "dma-mem", "write";
				//iommus = <&smmu_niso1 TEGRA234_SID_VIC>;
				//dma-coherent;
				status = "okay";
			};

			nvdec@15480000 {
				compatible = "nvidia,tegra234-nvdec";
				reg = <0x0 0x15480000 0x0 0x00040000>;
				clocks = <&bpmp TEGRA234_CLK_NVDEC>,
					 <&bpmp TEGRA234_CLK_FUSE>,
					 <&bpmp TEGRA234_CLK_TSEC_PKA>;
				clock-names = "nvdec", "fuse", "tsec_pka";
				resets = <&bpmp TEGRA234_RESET_NVDEC>;
				reset-names = "nvdec";
				power-domains = <&bpmp TEGRA234_POWER_DOMAIN_NVDEC>;
				// interconnects = <&mc TEGRA234_MEMORY_CLIENT_NVDECSRD &emc>,
				// 		<&mc TEGRA234_MEMORY_CLIENT_NVDECSWR &emc>;
				// interconnect-names = "dma-mem", "write";
				//iommus = <&smmu_niso1 TEGRA234_SID_NVDEC>;
				//dma-coherent;

				// nvidia,memory-controller = <&mc>;

				/*
				 * Placeholder values that firmware needs to update with the real
				 * offsets parsed from the microcode headers.
				 */
				// nvidia,bl-manifest-offset = <0>;
				// nvidia,bl-data-offset = <0>;
				// nvidia,bl-code-offset = <0>;
				// nvidia,os-manifest-offset = <0>;
				// nvidia,os-data-offset = <0>;
				// nvidia,os-code-offset = <0>;

				/*
				 * Firmware needs to set this to "okay" once the above values have
				 * been updated.
				 */
				status = "disabled";
			};

			nvjpg@15540000 {
				compatible = "nvidia,tegra234-nvjpg";
				reg = <0x0 0x15540000 0x0 0x00040000>;
				clocks = <&bpmp TEGRA234_CLK_NVJPG1>;
				clock-names = "nvjpg";
				resets = <&bpmp TEGRA234_RESET_NVJPG1>;
				reset-names = "nvjpg";

				power-domains = <&bpmp TEGRA234_POWER_DOMAIN_NVJPGB>;
				// interconnects = <&mc TEGRA234_MEMORY_CLIENT_NVJPG1SRD &emc>,
				// 		<&mc TEGRA234_MEMORY_CLIENT_NVJPG1SWR &emc>;
				// interconnect-names = "dma-mem", "write";
				//iommus = <&smmu_niso0 TEGRA234_SID_NVJPG1>;
				//dma-coherent;

				// Need to be enable in order that GPU interrupts works
				nvidia,host1x-class = <0x07>;
				status = "okay";
			};
		};



	};

	// Define the carveouts regions for the carveouts driver
	tegra-carveouts {
		compatible = "nvidia,carveouts";
		memory-region = <&generic_reserved &vpr &fsi_reserved &vidmem_reserved &gpu_reserved>;
		status = "okay";
	};

	fw-cfg@9020000 {
		dma-coherent;
		reg = <0x00 0x9020000 0x00 0x18>;
		compatible = "qemu,fw-cfg-mmio";
	};

	virtio_mmio@a000000 {
		dma-coherent;
		interrupts = <0x00 0x10 0x01>;
		reg = <0x00 0xa000000 0x00 0x200>;
		compatible = "virtio,mmio";
	};

	virtio_mmio@a000200 {
		dma-coherent;
		interrupts = <0x00 0x11 0x01>;
		reg = <0x00 0xa000200 0x00 0x200>;
		compatible = "virtio,mmio";
	};

	virtio_mmio@a000400 {
		dma-coherent;
		interrupts = <0x00 0x12 0x01>;
		reg = <0x00 0xa000400 0x00 0x200>;
		compatible = "virtio,mmio";
	};

	virtio_mmio@a000600 {
		dma-coherent;
		interrupts = <0x00 0x13 0x01>;
		reg = <0x00 0xa000600 0x00 0x200>;
		compatible = "virtio,mmio";
	};

	virtio_mmio@a000800 {
		dma-coherent;
		interrupts = <0x00 0x14 0x01>;
		reg = <0x00 0xa000800 0x00 0x200>;
		compatible = "virtio,mmio";
	};

	virtio_mmio@a000a00 {
		dma-coherent;
		interrupts = <0x00 0x15 0x01>;
		reg = <0x00 0xa000a00 0x00 0x200>;
		compatible = "virtio,mmio";
	};

	virtio_mmio@a000c00 {
		dma-coherent;
		interrupts = <0x00 0x16 0x01>;
		reg = <0x00 0xa000c00 0x00 0x200>;
		compatible = "virtio,mmio";
	};

	virtio_mmio@a000e00 {
		dma-coherent;
		interrupts = <0x00 0x17 0x01>;
		reg = <0x00 0xa000e00 0x00 0x200>;
		compatible = "virtio,mmio";
	};

	virtio_mmio@a001000 {
		dma-coherent;
		interrupts = <0x00 0x18 0x01>;
		reg = <0x00 0xa001000 0x00 0x200>;
		compatible = "virtio,mmio";
	};

	virtio_mmio@a001200 {
		dma-coherent;
		interrupts = <0x00 0x19 0x01>;
		reg = <0x00 0xa001200 0x00 0x200>;
		compatible = "virtio,mmio";
	};

	virtio_mmio@a001400 {
		dma-coherent;
		interrupts = <0x00 0x1a 0x01>;
		reg = <0x00 0xa001400 0x00 0x200>;
		compatible = "virtio,mmio";
	};

	virtio_mmio@a001600 {
		dma-coherent;
		interrupts = <0x00 0x1b 0x01>;
		reg = <0x00 0xa001600 0x00 0x200>;
		compatible = "virtio,mmio";
	};

	virtio_mmio@a001800 {
		dma-coherent;
		interrupts = <0x00 0x1c 0x01>;
		reg = <0x00 0xa001800 0x00 0x200>;
		compatible = "virtio,mmio";
	};

	virtio_mmio@a001a00 {
		dma-coherent;
		interrupts = <0x00 0x1d 0x01>;
		reg = <0x00 0xa001a00 0x00 0x200>;
		compatible = "virtio,mmio";
	};

	virtio_mmio@a001c00 {
		dma-coherent;
		interrupts = <0x00 0x1e 0x01>;
		reg = <0x00 0xa001c00 0x00 0x200>;
		compatible = "virtio,mmio";
	};

	virtio_mmio@a001e00 {
		dma-coherent;
		interrupts = <0x00 0x1f 0x01>;
		reg = <0x00 0xa001e00 0x00 0x200>;
		compatible = "virtio,mmio";
	};

	virtio_mmio@a002000 {
		dma-coherent;
		interrupts = <0x00 0x20 0x01>;
		reg = <0x00 0xa002000 0x00 0x200>;
		compatible = "virtio,mmio";
	};

	virtio_mmio@a002200 {
		dma-coherent;
		interrupts = <0x00 0x21 0x01>;
		reg = <0x00 0xa002200 0x00 0x200>;
		compatible = "virtio,mmio";
	};

	virtio_mmio@a002400 {
		dma-coherent;
		interrupts = <0x00 0x22 0x01>;
		reg = <0x00 0xa002400 0x00 0x200>;
		compatible = "virtio,mmio";
	};

	virtio_mmio@a002600 {
		dma-coherent;
		interrupts = <0x00 0x23 0x01>;
		reg = <0x00 0xa002600 0x00 0x200>;
		compatible = "virtio,mmio";
	};

	virtio_mmio@a002800 {
		dma-coherent;
		interrupts = <0x00 0x24 0x01>;
		reg = <0x00 0xa002800 0x00 0x200>;
		compatible = "virtio,mmio";
	};

	virtio_mmio@a002a00 {
		dma-coherent;
		interrupts = <0x00 0x25 0x01>;
		reg = <0x00 0xa002a00 0x00 0x200>;
		compatible = "virtio,mmio";
	};

	virtio_mmio@a002c00 {
		dma-coherent;
		interrupts = <0x00 0x26 0x01>;
		reg = <0x00 0xa002c00 0x00 0x200>;
		compatible = "virtio,mmio";
	};

	virtio_mmio@a002e00 {
		dma-coherent;
		interrupts = <0x00 0x27 0x01>;
		reg = <0x00 0xa002e00 0x00 0x200>;
		compatible = "virtio,mmio";
	};

	virtio_mmio@a003000 {
		dma-coherent;
		interrupts = <0x00 0x28 0x01>;
		reg = <0x00 0xa003000 0x00 0x200>;
		compatible = "virtio,mmio";
	};

	virtio_mmio@a003200 {
		dma-coherent;
		interrupts = <0x00 0x29 0x01>;
		reg = <0x00 0xa003200 0x00 0x200>;
		compatible = "virtio,mmio";
	};

	virtio_mmio@a003400 {
		dma-coherent;
		interrupts = <0x00 0x2a 0x01>;
		reg = <0x00 0xa003400 0x00 0x200>;
		compatible = "virtio,mmio";
	};

	virtio_mmio@a003600 {
		dma-coherent;
		interrupts = <0x00 0x2b 0x01>;
		reg = <0x00 0xa003600 0x00 0x200>;
		compatible = "virtio,mmio";
	};

	virtio_mmio@a003800 {
		dma-coherent;
		interrupts = <0x00 0x2c 0x01>;
		reg = <0x00 0xa003800 0x00 0x200>;
		compatible = "virtio,mmio";
	};

	virtio_mmio@a003a00 {
		dma-coherent;
		interrupts = <0x00 0x2d 0x01>;
		reg = <0x00 0xa003a00 0x00 0x200>;
		compatible = "virtio,mmio";
	};

	virtio_mmio@a003c00 {
		dma-coherent;
		interrupts = <0x00 0x2e 0x01>;
		reg = <0x00 0xa003c00 0x00 0x200>;
		compatible = "virtio,mmio";
	};

	virtio_mmio@a003e00 {
		dma-coherent;
		interrupts = <0x00 0x2f 0x01>;
		reg = <0x00 0xa003e00 0x00 0x200>;
		compatible = "virtio,mmio";
	};

	gpio-keys {
		compatible = "gpio-keys";

		poweroff {
			gpios = <0x8007 0x03 0x00>;
			linux,code = <0x74>;
			label = "GPIO Key Poweroff";
		};
	};

	pl061@9030000 {
		phandle = <0x8007>;
		clock-names = "apb_pclk";
		clocks = <0x8000>;
		interrupts = <0x00 0x07 0x04>;
		gpio-controller;
		#gpio-cells = <0x02>;
		compatible = "arm,pl061\0arm,primecell";
		reg = <0x00 0x9030000 0x00 0x1000>;
	};

	pcie@10000000 {
		interrupt-map-mask = <0x1800 0x00 0x00 0x07>;
		interrupt-map = <0x00 0x00 0x00 0x01 0x8005 0x00 0x00 0x00 0x03 0x04 0x00 0x00 0x00 0x02 0x8005 0x00 0x00 0x00 0x04 0x04 0x00 0x00 0x00 0x03 0x8005 0x00 0x00 0x00 0x05 0x04 0x00 0x00 0x00 0x04 0x8005 0x00 0x00 0x00 0x06 0x04 0x800 0x00 0x00 0x01 0x8005 0x00 0x00 0x00 0x04 0x04 0x800 0x00 0x00 0x02 0x8005 0x00 0x00 0x00 0x05 0x04 0x800 0x00 0x00 0x03 0x8005 0x00 0x00 0x00 0x06 0x04 0x800 0x00 0x00 0x04 0x8005 0x00 0x00 0x00 0x03 0x04 0x1000 0x00 0x00 0x01 0x8005 0x00 0x00 0x00 0x05 0x04 0x1000 0x00 0x00 0x02 0x8005 0x00 0x00 0x00 0x06 0x04 0x1000 0x00 0x00 0x03 0x8005 0x00 0x00 0x00 0x03 0x04 0x1000 0x00 0x00 0x04 0x8005 0x00 0x00 0x00 0x04 0x04 0x1800 0x00 0x00 0x01 0x8005 0x00 0x00 0x00 0x06 0x04 0x1800 0x00 0x00 0x02 0x8005 0x00 0x00 0x00 0x03 0x04 0x1800 0x00 0x00 0x03 0x8005 0x00 0x00 0x00 0x04 0x04 0x1800 0x00 0x00 0x04 0x8005 0x00 0x00 0x00 0x05 0x04>;
		#interrupt-cells = <0x01>;
		ranges = <0x1000000 0x00 0x00 0x00 0x3eff0000 0x00 0x10000 0x2000000 0x00 0x10000000 0x00 0x10000000 0x00 0x2eff0000 0x3000000 0x80 0x00 0x80 0x00 0x80 0x00>;
		reg = <0x5f 0xd0000000 0x00 0x10000000>;
		msi-map = <0x00 0x8006 0x00 0x10000>;
		dma-coherent;
		bus-range = <0x00 0xff>;
		linux,pci-domain = <0x00>;
		#size-cells = <0x02>;
		#address-cells = <0x03>;
		device_type = "pci";
		compatible = "pci-host-ecam-generic";
	};

	pl031@9010000 {
		clock-names = "apb_pclk";
		clocks = <0x8000>;
		interrupts = <0x00 0x02 0x04>;
		reg = <0x00 0x9010000 0x00 0x1000>;
		compatible = "arm,pl031\0arm,primecell";
	};

	pl011@9000000 {
		clock-names = "uartclk\0apb_pclk";
		clocks = <0x8000 0x8000>;
		interrupts = <0x00 0x01 0x04>;
		reg = <0x00 0x9000000 0x00 0x1000>;
		compatible = "arm,pl011\0arm,primecell";
	};

	pmu {
		interrupts = <0x01 0x07 0x04>;
		compatible = "arm,armv8-pmuv3";
	};

	intc@8000000 {
		phandle = <0x8005>;
		reg = <0x00 0x8000000 0x00 0x10000 0x00 0x80a0000 0x00 0xf60000>;
		#redistributor-regions = <0x01>;
		compatible = "arm,gic-v3";
		ranges;
		#size-cells = <0x02>;
		#address-cells = <0x02>;
		interrupt-controller;
		#interrupt-cells = <0x03>;

		its@8080000 {
			phandle = <0x8006>;
			reg = <0x00 0x8080000 0x00 0x20000>;
			#msi-cells = <0x01>;
			msi-controller;
			compatible = "arm,gic-v3-its";
		};
	};

	flash@0 {
		bank-width = <0x04>;
		reg = <0x00 0x00 0x00 0x4000000 0x00 0x4000000 0x00 0x4000000>;
		compatible = "cfi-flash";
	};

	cpus {
		#size-cells = <0x00>;
		#address-cells = <0x01>;

		cpu-map {

			socket0 {

				cluster0 {

					core0 {
						cpu = <0x8004>;
					};

					core1 {
						cpu = <0x8003>;
					};

					core2 {
						cpu = <0x8002>;
					};

					core3 {
						cpu = <0x8001>;
					};
				};
			};
		};

		cpu@0 {
			phandle = <0x8004>;
			reg = <0x00>;
			enable-method = "psci";
			compatible = "arm,arm-v8";
			device_type = "cpu";
		};

		cpu@1 {
			phandle = <0x8003>;
			reg = <0x01>;
			enable-method = "psci";
			compatible = "arm,arm-v8";
			device_type = "cpu";
		};

		cpu@2 {
			phandle = <0x8002>;
			reg = <0x02>;
			enable-method = "psci";
			compatible = "arm,arm-v8";
			device_type = "cpu";
		};

		cpu@3 {
			phandle = <0x8001>;
			reg = <0x03>;
			enable-method = "psci";
			compatible = "arm,arm-v8";
			device_type = "cpu";
		};
	};

	timer {
		interrupts = <0x01 0x0d 0x04 0x01 0x0e 0x04 0x01 0x0b 0x04 0x01 0x0a 0x04>;
		always-on;
		compatible = "arm,armv8-timer\0arm,armv7-timer";
	};

	apb-pclk {
		phandle = <0x8000>;
		clock-output-names = "clk24mhz";
		clock-frequency = <0x16e3600>;
		#clock-cells = <0x00>;
		compatible = "fixed-clock";
	};

	chosen {
		bootargs = "rootwait root=/dev/vda console=ttyAMA0";
		stdout-path = "/pl011@9000000";
		rng-seed = <0x67b6f34f 0xc86e63c5 0xa358bcaa 0x4433845d 0xe55d22f3 0xbf39d920 0x8fd3366d 0x15f35a5b>;
		kaslr-seed = <0xca4d66e8 0xda2a6750>;
		#address-cells = <1>;
		#size-cells = <1>;
	};
};
